LIN_description_file;
LIN_protocol_version = "2.2";
LIN_language_version = "2.2";
LIN_speed = 19.2 kbps;

Nodes {
  Master: LIN_Master, 1 ms, 0 ms ;
  Slaves: LIN_1, LIN_2 ;
}

Signals {
  run_state: 8, 0, LIN_1, LIN_Master ;
  err_state: 8, 0, LIN_1, LIN_Master ;
  led_state: 8, 0, LIN_1, LIN_Master ;
  run2_state: 8, 0, LIN_2, LIN_Master ;
  err2_state: 8, 0, LIN_2, LIN_Master ;
  led2_state: 8, 0, LIN_2, LIN_Master ;
  LIN1_Config_Signal: 8, {0}, LIN_Master, LIN_1 ;
  LIN2_Config_NewSignal: 8, {0}, LIN_Master, LIN_2 ;
  LIN1_Config_Check_NewSignal: 8, 0, LIN_1, LIN_Master ;
  LIN1_Config_Check_ID: 8, 133, LIN_1, LIN_Master ;
  LIN2_Config_Check_Signal: 8, 0, LIN_2, LIN_Master ;
  LIN2_Config_Check_ID: 8, 6, LIN_2, LIN_Master ;
}

Frames {
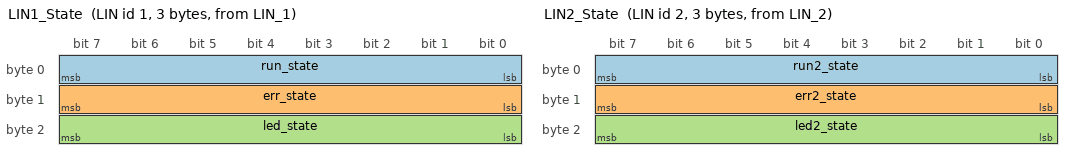
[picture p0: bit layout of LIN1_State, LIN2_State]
  LIN1_State: 1, LIN_1, 3 {
    run_state, 0 ;
    err_state, 8 ;
    led_state, 16 ;
  }
  LIN2_State: 2, LIN_2, 3 {
    run2_state, 0 ;
    err2_state, 8 ;
    led2_state, 16 ;
  }
  LIN1_Config: 4, LIN_Master, 8 {
    LIN1_Config_Signal, 0 ;
  }
  LIN2_Config: 3, LIN_Master, 8 {
    LIN2_Config_NewSignal, 0 ;
  }
  LIN1_Config_Check: 5, LIN_1, 2 {
    LIN1_Config_Check_NewSignal, 8 ;
    LIN1_Config_Check_ID, 0 ;
  }
  LIN2_Config_Check: 6, LIN_2, 2 {
    LIN2_Config_Check_Signal, 8 ;
    LIN2_Config_Check_ID, 0 ;
  }
}

Sporadic_frames {
  Config_Set: LIN1_Config, LIN2_Config ;
}

Event_triggered_frames {
  Config_Check: table2, 7, LIN1_Config_Check, LIN2_Config_Check ;
}

Node_attributes {
  LIN_1{
    LIN_protocol = "2.2" ;
    configured_NAD = 0x1 ;
    initial_NAD = 0x2 ;
    product_id = 0x0, 0x0, 255 ;
    P2_min = 50 ms ;
    ST_min = 0 ms ;
    N_As_timeout = 1000 ms ;
    N_Cr_timeout = 1000 ms ;
    configurable_frames {
      LIN1_State ;
      LIN1_Config ;
      LIN1_Config_Check ;
      Config_Check ;
    }
  }
  LIN_2{
    LIN_protocol = "2.2" ;
    configured_NAD = 0x2 ;
    initial_NAD = 0x2 ;
    product_id = 0x0, 0x0, 255 ;
    P2_min = 50 ms ;
    ST_min = 0 ms ;
    N_As_timeout = 1000 ms ;
    N_Cr_timeout = 1000 ms ;
    configurable_frames {
      LIN2_State ;
      LIN2_Config ;
      LIN2_Config_Check ;
      Config_Check ;
    }
  }
}

Schedule_tables {
 table1 {
    Config_Check delay 10 ms ;
    Config_Set delay 10 ms ;
    LIN1_State delay 10 ms ;
    LIN2_State delay 10 ms ;
  }
 table2 {
    LIN1_Config_Check delay 10 ms ;
    LIN2_Config_Check delay 10 ms ;
  }
 dq {
    MasterReq delay 10 ms ;
  }
 ds {
    SlaveResp delay 10 ms ;
  }
}

Signal_encoding_types {
  run_state_Encoding {
    physical_value, 0, 2, 1, 0 ;
    logical_value, 0, "init_val" ;
    logical_value, 1, "val1" ;
    logical_value, 2, "val2" ;
  }
}

Signal_representation {
  run_state_Encoding: run_state ;
}
